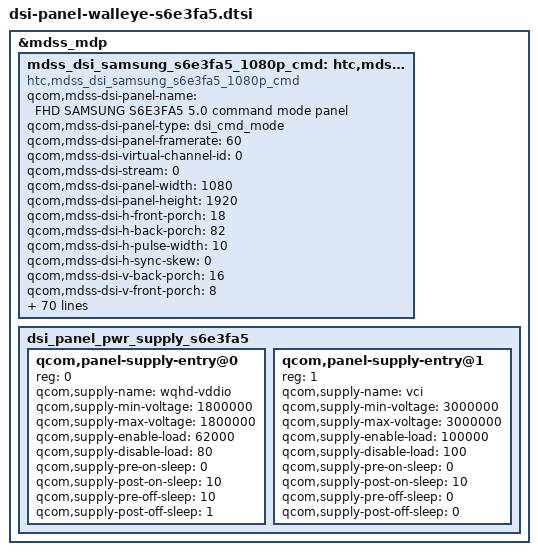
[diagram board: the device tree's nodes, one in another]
/* Copyright (c) 2016, The Linux Foundation. All rights reserved.
 *
 * This program is free software; you can redistribute it and/or modify
 * it under the terms of the GNU General Public License version 2 and
 * only version 2 as published by the Free Software Foundation.
 *
 * This program is distributed in the hope that it will be useful,
 * but WITHOUT ANY WARRANTY; without even the implied warranty of
 * MERCHANTABILITY or FITNESS FOR A PARTICULAR PURPOSE.  See the
 * GNU General Public License for more details.
 */
&mdss_mdp {
	mdss_dsi_samsung_s6e3fa5_1080p_cmd: htc,mdss_dsi_samsung_s6e3fa5_1080p_cmd {
		compatible = "htc,mdss_dsi_samsung_s6e3fa5_1080p_cmd";
		qcom,mdss-dsi-panel-name = "FHD SAMSUNG S6E3FA5 5.0 command mode panel";
		qcom,mdss-dsi-panel-type = "dsi_cmd_mode";
		qcom,mdss-dsi-panel-framerate = <60>;
		qcom,mdss-dsi-virtual-channel-id = <0>;
		qcom,mdss-dsi-stream = <0>;
		qcom,mdss-dsi-panel-width = <1080>;
		qcom,mdss-dsi-panel-height = <1920>;
		qcom,mdss-dsi-h-front-porch = <18>;
		qcom,mdss-dsi-h-back-porch = <82>;
		qcom,mdss-dsi-h-pulse-width = <10>;
		qcom,mdss-dsi-h-sync-skew = <0>;
		qcom,mdss-dsi-v-back-porch = <16>;
		qcom,mdss-dsi-v-front-porch = <8>;
		qcom,mdss-dsi-v-pulse-width = <2>;
		qcom,mdss-dsi-h-left-border = <0>;
		qcom,mdss-dsi-h-right-border = <0>;
		qcom,mdss-dsi-v-top-border = <0>;
		qcom,mdss-dsi-v-bottom-border = <0>;
		qcom,mdss-pan-physical-width-dimension  = <62>;
		qcom,mdss-pan-physical-height-dimension = <110>;
		qcom,mdss-dsi-bpp = <24>;
		qcom,mdss-dsi-color-order = "rgb_swap_rgb";
		qcom,mdss-dsi-underflow-color = <0xff>;
		qcom,mdss-dsi-border-color = <0>;
		qcom,mdss-dsi-h-sync-pulse = <0>;
		qcom,mdss-dsi-traffic-mode = "non_burst_sync_event";
		qcom,mdss-dsi-lane-map = "lane_map_0123";
		qcom,mdss-dsi-bllp-eof-power-mode;
		qcom,mdss-dsi-bllp-power-mode;
		qcom,mdss-dsi-panel-broadcast-mode;
		qcom,mdss-dsi-lane-0-state;
		qcom,mdss-dsi-lane-1-state;
		qcom,mdss-dsi-lane-2-state;
		qcom,mdss-dsi-lane-3-state;
		/* 833Mbps */
		qcom,mdss-dsi-panel-timings = [00 1B 05 06 0A 0E 07 06 05 03 04 00];
		qcom,mdss-dsi-t-clk-post = <0x07>;
		qcom,mdss-dsi-t-clk-pre = <0x28>;
		qcom,mdss-dsi-reset-sequence =  <1 1>, <0 1>, <1 10>;
		qcom,mdss-dsi-bl-pmic-control-type = "bl_ctrl_dcs";
		qcom,mdss-dsi-bl-min-level = <1>;
		qcom,mdss-dsi-bl-max-level = <255>;
		qcom,mdss-dsi-dma-trigger = "trigger_sw";
		qcom,mdss-dsi-mdp-trigger = "none";
		qcom,mdss-dsi-wr-mem-start = <0x2c>;
		qcom,mdss-dsi-wr-mem-continue = <0x3c>;
		qcom,mdss-dsi-te-pin-select = <1>;
		qcom,mdss-dsi-te-dcs-command = <1>;
		qcom,mdss-dsi-te-check-enable;
		qcom,mdss-dsi-te-using-te-pin;
		qcom,dcs-cmd-by-left;
		qcom,ulps-enabled;
		qcom,mdss-dsi-on-command = [
			05 01 00 00 78 00 02 11 00 /* sleep out */
			05 01 00 00 00 00 02 35 00 /* TE on */
			15 01 00 00 00 00 02 53 20 /* brightness control (dimming) */
			29 01 00 00 00 00 03 F0 5A 5A
			39 01 00 00 00 00 06 BB 54 00 36 20 F3
			29 01 00 00 00 00 03 F0 A5 A5
			05 01 00 00 00 00 02 29 00 /* display on */
		];
		qcom,mdss-dsi-on-command-state = "dsi_lp_mode";
		qcom,mdss-dsi-off-command = [
			05 01 00 00 0A 00 02 28 00
			05 01 00 00 96 00 02 10 00
		];
		qcom,mdss-dsi-off-command-state = "dsi_hs_mode";
		/* qcom,mdss-dsi-default-command-state = "dsi_hs_mode"; */
		qcom,cont-splash-enabled;
		qcom,mdss-dsi-lp11-init;
		qcom,panel-supply-entries = <&dsi_panel_pwr_supply_s6e3fa5>;
		qcom,alpm-bl-threshold = <27>;
		qcom,alpm-off-command = [
			29 01 00 00 00 00 03 F0 5A 5A
			39 01 00 00 00 00 02 B0 1C
			39 01 00 00 00 00 02 B5 20
			15 01 00 00 00 00 02 53 20
			29 01 00 00 00 00 03 F0 A5 A5
		];
		qcom,alpm-low-command = [
			29 01 00 00 00 00 03 F0 5A 5A
			05 01 00 00 12 00 01 22
			39 01 00 00 00 00 02 B0 1C
			39 01 00 00 00 00 02 B5 50
			15 01 00 00 00 00 02 51 04
			15 01 00 00 12 00 02 53 23
			15 01 00 00 32 00 02 53 20
			15 01 00 00 00 00 02 53 23
			05 01 00 00 00 00 01 13
			29 01 00 00 00 00 03 F0 A5 A5
		];
		qcom,alpm-high-command = [
			29 01 00 00 00 00 03 F0 5A 5A
			05 01 00 00 12 00 01 22
			39 01 00 00 00 00 02 B0 1C
			39 01 00 00 00 00 02 B5 50
			15 01 00 00 00 00 02 51 19
			15 01 00 00 12 00 02 53 22
			15 01 00 00 32 00 02 53 20
			15 01 00 00 00 00 02 53 22
			05 01 00 00 00 00 01 13
			29 01 00 00 00 00 03 F0 A5 A5
		];
		qcom,alpm-low-transition-command = [
			15 01 00 00 00 00 02 51 04
			15 01 00 00 00 00 02 53 23
		];
		qcom,alpm-high-transition-command = [
			15 01 00 00 00 00 02 51 19
			15 01 00 00 00 00 02 53 22
		];
		qcom,mdss-dsi-lp-mode-on = [
			29 01 00 00 00 00 03 F0 5A 5A
			29 01 00 00 00 00 02 B0 0A
			29 01 00 00 00 00 03 CB 03 0E
			29 01 00 00 00 00 02 B0 1F
			29 01 00 00 00 00 02 CB 15
			29 01 00 00 00 00 02 B0 3B
			29 01 00 00 00 00 02 CB 80
			29 01 00 00 00 00 03 B1 02 40
			29 01 00 00 00 00 02 F7 03
			29 01 00 00 00 00 03 F0 A5 A5
		];
		qcom,mdss-dsi-lp-mode-off = [
			29 01 00 00 00 00 03 F0 5A 5A
			29 01 00 00 00 00 02 B0 0A
			29 01 00 00 00 00 03 CB 0B 06
			29 01 00 00 00 00 02 B0 1F
			29 01 00 00 00 00 02 CB 09
			29 01 00 00 00 00 02 B0 3B
			29 01 00 00 00 00 02 CB 00
			29 01 00 00 00 00 03 B1 80 40
			29 01 00 00 00 00 02 F7 03
			29 01 00 00 00 00 03 F0 A5 A5
		];
		qcom,mdss-dsi-lp-change-state = "dsi_hs_mode";
		qcom,mdss-dsi-gain-on-command = [
			29 01 00 00 00 00 03 F0 5A 5A
			29 01 00 00 00 00 03 F1 5A 5A
			29 01 00 00 00 00 07 C8 00 00 00 00 00 00
			29 01 00 00 00 00 02 F7 03
			29 01 00 00 00 00 03 F0 A5 A5
			29 01 00 00 00 00 03 F1 A5 A5
		];
		qcom,mdss-dsi-rgb-gain-offset = <2 1 2>;
	};
	dsi_panel_pwr_supply_s6e3fa5: dsi_panel_pwr_supply_s6e3fa5 {
		#address-cells = <1>;
		#size-cells = <0>;
		qcom,panel-supply-entry@0 {
			reg = <0>;
			qcom,supply-name = "wqhd-vddio";
			qcom,supply-min-voltage = <1800000>;
			qcom,supply-max-voltage = <1800000>;
			qcom,supply-enable-load = <62000>;
			qcom,supply-disable-load = <80>;
			qcom,supply-pre-on-sleep = <0>;
			qcom,supply-post-on-sleep = <10>;
			qcom,supply-pre-off-sleep = <10>;
			qcom,supply-post-off-sleep = <1>;
		};
		qcom,panel-supply-entry@1 {
			reg = <1>;
			qcom,supply-name = "vci";
			qcom,supply-min-voltage = <3000000>;
			qcom,supply-max-voltage = <3000000>;
			qcom,supply-enable-load = <100000>;
			qcom,supply-disable-load = <100>;
			qcom,supply-pre-on-sleep = <0>;
			qcom,supply-post-on-sleep = <10>;
			qcom,supply-pre-off-sleep = <0>;
			qcom,supply-post-off-sleep = <0>;
		 };
	};
};
